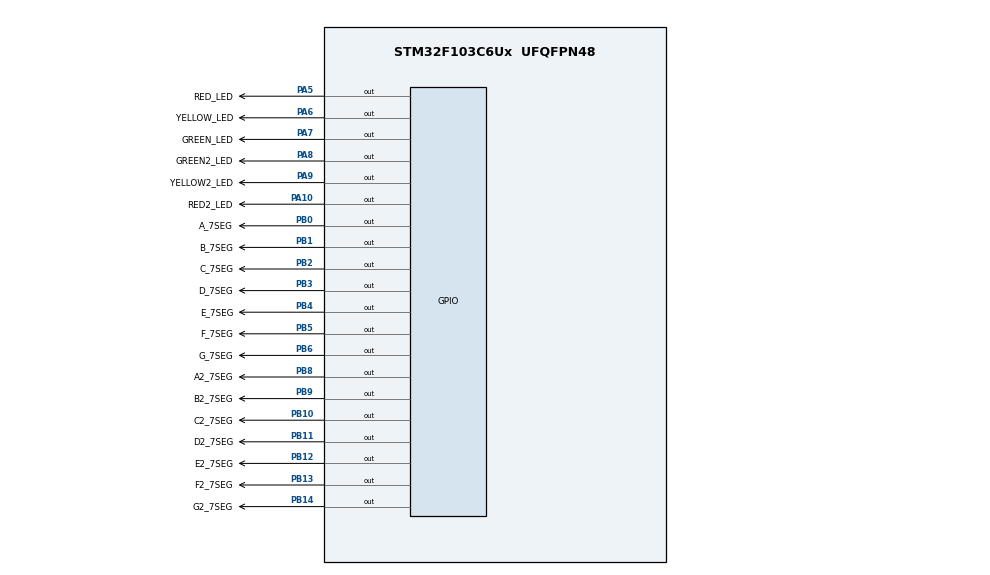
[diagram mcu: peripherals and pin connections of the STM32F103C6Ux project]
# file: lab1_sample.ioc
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Mcu.Family=STM32F1
Mcu.Name=STM32F103C6Ux
Mcu.Package=UFQFPN48
NVIC.PriorityGroup=NVIC_PRIORITYGROUP_4
PA10.GPIO_Label=RED2_LED
PA10.Signal=GPIO_Output
PA5.GPIO_Label=RED_LED
PA5.Signal=GPIO_Output
PA6.GPIO_Label=YELLOW_LED
PA6.Signal=GPIO_Output
PA7.GPIO_Label=GREEN_LED
PA7.Signal=GPIO_Output
PA8.GPIO_Label=GREEN2_LED
PA8.Signal=GPIO_Output
PA9.GPIO_Label=YELLOW2_LED
PA9.Signal=GPIO_Output
PB0.GPIO_Label=A_7SEG
PB0.Signal=GPIO_Output
PB1.GPIO_Label=B_7SEG
PB1.Signal=GPIO_Output
PB10.GPIO_Label=C2_7SEG
PB10.Signal=GPIO_Output
PB11.GPIO_Label=D2_7SEG
PB11.Signal=GPIO_Output
PB12.GPIO_Label=E2_7SEG
PB12.Signal=GPIO_Output
PB13.GPIO_Label=F2_7SEG
PB13.Signal=GPIO_Output
PB14.GPIO_Label=G2_7SEG
PB14.Signal=GPIO_Output
PB2.GPIO_Label=C_7SEG
PB2.Signal=GPIO_Output
PB3.GPIO_Label=D_7SEG
PB3.Signal=GPIO_Output
PB4.GPIO_Label=E_7SEG
PB4.Signal=GPIO_Output
PB5.GPIO_Label=F_7SEG
PB5.Signal=GPIO_Output
PB6.GPIO_Label=G_7SEG
PB6.Signal=GPIO_Output
PB8.GPIO_Label=A2_7SEG
PB8.Signal=GPIO_Output
PB9.GPIO_Label=B2_7SEG
PB9.Signal=GPIO_Output
ProjectManager.HeapSize=0x200
ProjectManager.StackSize=0x400
ProjectManager.TargetToolchain=STM32CubeIDE
RCC.APB1Freq_Value=8000000
RCC.APB2Freq_Value=8000000
VP_SYS_VS_ND.Mode=No_Debug
board=custom

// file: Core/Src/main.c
/* USER CODE BEGIN Header */
/**
  ******************************************************************************
  * @file           : main.c
  * @brief          : Main program body
  ******************************************************************************
  * @attention
  *
  * <h2><center>&copy; Copyright (c) 2021 STMicroelectronics.
  * All rights reserved.</center></h2>
  *
  * This software component is licensed by ST under BSD 3-Clause license,
  * the "License"; You may not use this file except in compliance with the
  * License. You may obtain a copy of the License at:
  *                        opensource.org/licenses/BSD-3-Clause
  *
  ******************************************************************************
  */
/* USER CODE END Header */
#include "main.h"

/* USER CODE BEGIN Includes */
#include "7segclock.h"
/* USER CODE END Includes */

void SystemClock_Config(void);
static void MX_GPIO_Init(void);

/* USER CODE BEGIN 0 */

/*// for exercise 4
uint8_t counter = 0;*/

/* USER CODE END 0 */

int main(void)
{

  /* MCU Configuration--------------------------------------------------------*/

  /* Reset of all peripherals, Initializes the Flash interface and the Systick. */
  HAL_Init();

  /* Configure the system clock */
  SystemClock_Config();

  /* Initialize all configured peripherals */
  MX_GPIO_Init();
  /* USER CODE BEGIN 2 */
/*  uint8_t counter = 0;*/
  /* USER CODE END 2 */

  /* Infinite loop */
  while (1)
  {
/*	  // sample
	  HAL_GPIO_TogglePin(RED_LED_GPIO_Port, RED_LED_Pin);
	  HAL_Delay(1000);*/

/*	  // exercise 1
	  // 1
	  HAL_GPIO_WritePin(RED_LED_GPIO_Port, RED_LED_Pin, GPIO_PIN_RESET);
	  HAL_GPIO_WritePin(YELLOW_LED_GPIO_Port, YELLOW_LED_Pin, GPIO_PIN_SET);
	  HAL_Delay(2000);
	  // 2
	  HAL_GPIO_WritePin(RED_LED_GPIO_Port, RED_LED_Pin, GPIO_PIN_SET);
	  HAL_GPIO_WritePin(YELLOW_LED_GPIO_Port, YELLOW_LED_Pin, GPIO_PIN_RESET);
	  HAL_Delay(2000);*/

/*	  // exercise 2
	  // 1
	  HAL_GPIO_WritePin(RED_LED_GPIO_Port, RED_LED_Pin, GPIO_PIN_RESET);
	  HAL_GPIO_WritePin(YELLOW_LED_GPIO_Port, YELLOW_LED_Pin, GPIO_PIN_SET);
	  HAL_GPIO_WritePin(GREEN_LED_GPIO_Port, GREEN_LED_Pin, GPIO_PIN_SET);
	  HAL_Delay(5000);
	  // 2
	  HAL_GPIO_WritePin(RED_LED_GPIO_Port, RED_LED_Pin, GPIO_PIN_SET);
	  HAL_GPIO_WritePin(YELLOW_LED_GPIO_Port, YELLOW_LED_Pin, GPIO_PIN_RESET);
	  HAL_GPIO_WritePin(GREEN_LED_GPIO_Port, GREEN_LED_Pin, GPIO_PIN_SET);
	  HAL_Delay(2000);
	  // 3
	  HAL_GPIO_WritePin(RED_LED_GPIO_Port, RED_LED_Pin, GPIO_PIN_SET);
	  HAL_GPIO_WritePin(YELLOW_LED_GPIO_Port, YELLOW_LED_Pin, GPIO_PIN_SET);
	  HAL_GPIO_WritePin(GREEN_LED_GPIO_Port, GREEN_LED_Pin, GPIO_PIN_RESET);
	  HAL_Delay(3000);*/

/*	  // exercise 3
	  // 1
	  HAL_GPIO_WritePin(RED_LED_GPIO_Port, RED_LED_Pin, GPIO_PIN_RESET);
	  HAL_GPIO_WritePin(YELLOW_LED_GPIO_Port, YELLOW_LED_Pin, GPIO_PIN_SET);
	  HAL_GPIO_WritePin(GREEN_LED_GPIO_Port, GREEN_LED_Pin, GPIO_PIN_SET);
	  // 1.2
	  HAL_GPIO_WritePin(RED2_LED_GPIO_Port, RED2_LED_Pin, GPIO_PIN_RESET);
	  HAL_GPIO_WritePin(YELLOW2_LED_GPIO_Port, YELLOW2_LED_Pin, GPIO_PIN_SET);
	  HAL_GPIO_WritePin(GREEN2_LED_GPIO_Port, GREEN2_LED_Pin, GPIO_PIN_SET);
	  // delay
	  HAL_Delay(5000);

	  // 2
	  HAL_GPIO_WritePin(RED_LED_GPIO_Port, RED_LED_Pin, GPIO_PIN_SET);
	  HAL_GPIO_WritePin(YELLOW_LED_GPIO_Port, YELLOW_LED_Pin, GPIO_PIN_RESET);
	  HAL_GPIO_WritePin(GREEN_LED_GPIO_Port, GREEN_LED_Pin, GPIO_PIN_SET);
	  // 2.2
	  HAL_GPIO_WritePin(RED2_LED_GPIO_Port, RED2_LED_Pin, GPIO_PIN_SET);
	  HAL_GPIO_WritePin(YELLOW2_LED_GPIO_Port, YELLOW2_LED_Pin, GPIO_PIN_RESET);
	  HAL_GPIO_WritePin(GREEN2_LED_GPIO_Port, GREEN2_LED_Pin, GPIO_PIN_SET);
	  // delay
	  HAL_Delay(2000);

	  // 3
	  HAL_GPIO_WritePin(RED_LED_GPIO_Port, RED_LED_Pin, GPIO_PIN_SET);
	  HAL_GPIO_WritePin(YELLOW_LED_GPIO_Port, YELLOW_LED_Pin, GPIO_PIN_SET);
	  HAL_GPIO_WritePin(GREEN_LED_GPIO_Port, GREEN_LED_Pin, GPIO_PIN_RESET);
	  // 3.2
	  HAL_GPIO_WritePin(RED2_LED_GPIO_Port, RED2_LED_Pin, GPIO_PIN_SET);
	  HAL_GPIO_WritePin(YELLOW2_LED_GPIO_Port, YELLOW2_LED_Pin, GPIO_PIN_SET);
	  HAL_GPIO_WritePin(GREEN2_LED_GPIO_Port, GREEN2_LED_Pin, GPIO_PIN_RESET);
	  // delay
	  HAL_Delay(3000);*/

/*	  // exercise 4
	  counter = (counter + 1)%10;
	  Buffer_Update_7seg(counter, 0);
	  Driver_7seg(0);
	  HAL_Delay(1000);*/

	  // exercise 5

	  // phase 1

	  // 1.1 horizontal red on
	  HAL_GPIO_WritePin(RED_LED_GPIO_Port, RED_LED_Pin, GPIO_PIN_RESET);
	  HAL_GPIO_WritePin(YELLOW_LED_GPIO_Port, YELLOW_LED_Pin, GPIO_PIN_SET);
	  HAL_GPIO_WritePin(GREEN_LED_GPIO_Port, GREEN_LED_Pin, GPIO_PIN_SET);
	  // 1.2 vertical green on
	  HAL_GPIO_WritePin(RED2_LED_GPIO_Port, RED2_LED_Pin, GPIO_PIN_SET);
	  HAL_GPIO_WritePin(YELLOW2_LED_GPIO_Port, YELLOW2_LED_Pin, GPIO_PIN_SET);
	  HAL_GPIO_WritePin(GREEN2_LED_GPIO_Port, GREEN2_LED_Pin, GPIO_PIN_RESET);
	  // clock
	  for (uint8_t cnt_red_1 = 9; cnt_red_1 > 0; cnt_red_1--) {
		  // red 9s
		  Buffer_Update_7seg(cnt_red_1, 0);
		  Driver_7seg(0);

		  // green 6s
		  uint8_t cnt_gre_2 = cnt_red_1 - 3;
		  if (cnt_gre_2 > 0) {
			  Buffer_Update_7seg(cnt_gre_2, 1);
			  Driver_7seg(1);
		  }

		  // yellow on
		  if (cnt_red_1 <= 3){
			  uint8_t cnt_yel_2 = cnt_red_1;
			  HAL_GPIO_WritePin(RED2_LED_GPIO_Port, RED2_LED_Pin, GPIO_PIN_SET);
			  HAL_GPIO_WritePin(YELLOW2_LED_GPIO_Port, YELLOW2_LED_Pin, GPIO_PIN_RESET);
			  HAL_GPIO_WritePin(GREEN2_LED_GPIO_Port, GREEN2_LED_Pin, GPIO_PIN_SET);
			  Buffer_Update_7seg(cnt_yel_2, 1);
			  Driver_7seg(1);
		  }
		  // delay
		  HAL_Delay(500);
	  }

	  // phase 2

	  // 2.1 horizontal green on
	  HAL_GPIO_WritePin(RED_LED_GPIO_Port, RED_LED_Pin, GPIO_PIN_SET);
	  HAL_GPIO_WritePin(YELLOW_LED_GPIO_Port, YELLOW_LED_Pin, GPIO_PIN_SET);
	  HAL_GPIO_WritePin(GREEN_LED_GPIO_Port, GREEN_LED_Pin, GPIO_PIN_RESET);
	  // 2.2 vertical red on
	  HAL_GPIO_WritePin(RED2_LED_GPIO_Port, RED2_LED_Pin, GPIO_PIN_RESET);
	  HAL_GPIO_WritePin(YELLOW2_LED_GPIO_Port, YELLOW2_LED_Pin, GPIO_PIN_SET);
	  HAL_GPIO_WritePin(GREEN2_LED_GPIO_Port, GREEN2_LED_Pin, GPIO_PIN_SET);
	  // clock
	  for (int cnt_red_2 = 9; cnt_red_2 > 0; cnt_red_2--) {
		  // red 9s
		  Buffer_Update_7seg(cnt_red_2, 1);
		  Driver_7seg(1);

		  // green 6s
		  uint8_t cnt_gre_1 = cnt_red_2 - 3;
		  if (cnt_gre_1 > 0) {
			  Buffer_Update_7seg(cnt_gre_1, 0);
			  Driver_7seg(0);
		  }

		  // yellow on
		  if (cnt_red_2 <= 3){
			  uint8_t cnt_yel_1 = cnt_red_2;
			  HAL_GPIO_WritePin(RED_LED_GPIO_Port, RED_LED_Pin, GPIO_PIN_SET);
			  HAL_GPIO_WritePin(YELLOW_LED_GPIO_Port, YELLOW_LED_Pin, GPIO_PIN_RESET);
			  HAL_GPIO_WritePin(GREEN_LED_GPIO_Port, GREEN_LED_Pin, GPIO_PIN_SET);
			  Buffer_Update_7seg(cnt_yel_1, 0);
			  Driver_7seg(0);
		  }
		  // delay
		  HAL_Delay(500);
	  }

  }
}

void SystemClock_Config(void)
{
  RCC_OscInitTypeDef RCC_OscInitStruct = {0};
  RCC_ClkInitTypeDef RCC_ClkInitStruct = {0};

  /** Initializes the RCC Oscillators according to the specified parameters
  * in the RCC_OscInitTypeDef structure.
  */
  RCC_OscInitStruct.OscillatorType = RCC_OSCILLATORTYPE_HSI;
  RCC_OscInitStruct.HSIState = RCC_HSI_ON;
  RCC_OscInitStruct.HSICalibrationValue = RCC_HSICALIBRATION_DEFAULT;
  RCC_OscInitStruct.PLL.PLLState = RCC_PLL_NONE;
  if (HAL_RCC_OscConfig(&RCC_OscInitStruct) != HAL_OK)
  {
    Error_Handler();
  }
  /** Initializes the CPU, AHB and APB buses clocks
  */
  RCC_ClkInitStruct.ClockType = RCC_CLOCKTYPE_HCLK|RCC_CLOCKTYPE_SYSCLK
                              |RCC_CLOCKTYPE_PCLK1|RCC_CLOCKTYPE_PCLK2;
  RCC_ClkInitStruct.SYSCLKSource = RCC_SYSCLKSOURCE_HSI;
  RCC_ClkInitStruct.AHBCLKDivider = RCC_SYSCLK_DIV1;
  RCC_ClkInitStruct.APB1CLKDivider = RCC_HCLK_DIV1;
  RCC_ClkInitStruct.APB2CLKDivider = RCC_HCLK_DIV1;

  if (HAL_RCC_ClockConfig(&RCC_ClkInitStruct, FLASH_LATENCY_0) != HAL_OK)
  {
    Error_Handler();
  }
}

static void MX_GPIO_Init(void)
{
  GPIO_InitTypeDef GPIO_InitStruct = {0};

  /* GPIO Ports Clock Enable */
  __HAL_RCC_GPIOA_CLK_ENABLE();
  __HAL_RCC_GPIOB_CLK_ENABLE();

  /*Configure GPIO pin Output Level */
  HAL_GPIO_WritePin(GPIOA, RED_LED_Pin|YELLOW_LED_Pin|GREEN_LED_Pin|GREEN2_LED_Pin
                          |YELLOW2_LED_Pin|RED2_LED_Pin, GPIO_PIN_RESET);

  /*Configure GPIO pin Output Level */
  HAL_GPIO_WritePin(GPIOB, A_7SEG_Pin|B_7SEG_Pin|C_7SEG_Pin|C2_7SEG_Pin
                          |D2_7SEG_Pin|E2_7SEG_Pin|F2_7SEG_Pin|G2_7SEG_Pin
                          |D_7SEG_Pin|E_7SEG_Pin|F_7SEG_Pin|G_7SEG_Pin
                          |A2_7SEG_Pin|B2_7SEG_Pin, GPIO_PIN_RESET);

  /*Configure GPIO pins : RED_LED_Pin YELLOW_LED_Pin GREEN_LED_Pin GREEN2_LED_Pin
                           YELLOW2_LED_Pin RED2_LED_Pin */
  GPIO_InitStruct.Pin = RED_LED_Pin|YELLOW_LED_Pin|GREEN_LED_Pin|GREEN2_LED_Pin
                          |YELLOW2_LED_Pin|RED2_LED_Pin;
  GPIO_InitStruct.Mode = GPIO_MODE_OUTPUT_PP;
  GPIO_InitStruct.Pull = GPIO_NOPULL;
  GPIO_InitStruct.Speed = GPIO_SPEED_FREQ_LOW;
  HAL_GPIO_Init(GPIOA, &GPIO_InitStruct);

  /*Configure GPIO pins : A_7SEG_Pin B_7SEG_Pin C_7SEG_Pin C2_7SEG_Pin
                           D2_7SEG_Pin E2_7SEG_Pin F2_7SEG_Pin G2_7SEG_Pin
                           D_7SEG_Pin E_7SEG_Pin F_7SEG_Pin G_7SEG_Pin
                           A2_7SEG_Pin B2_7SEG_Pin */
  GPIO_InitStruct.Pin = A_7SEG_Pin|B_7SEG_Pin|C_7SEG_Pin|C2_7SEG_Pin
                          |D2_7SEG_Pin|E2_7SEG_Pin|F2_7SEG_Pin|G2_7SEG_Pin
                          |D_7SEG_Pin|E_7SEG_Pin|F_7SEG_Pin|G_7SEG_Pin
                          |A2_7SEG_Pin|B2_7SEG_Pin;
  GPIO_InitStruct.Mode = GPIO_MODE_OUTPUT_PP;
  GPIO_InitStruct.Pull = GPIO_NOPULL;
  GPIO_InitStruct.Speed = GPIO_SPEED_FREQ_LOW;
  HAL_GPIO_Init(GPIOB, &GPIO_InitStruct);

}

void Error_Handler(void)
{
  __disable_irq();
  while (1)
  {
  }
}

/************************ (C) COPYRIGHT STMicroelectronics *****END OF FILE****/
